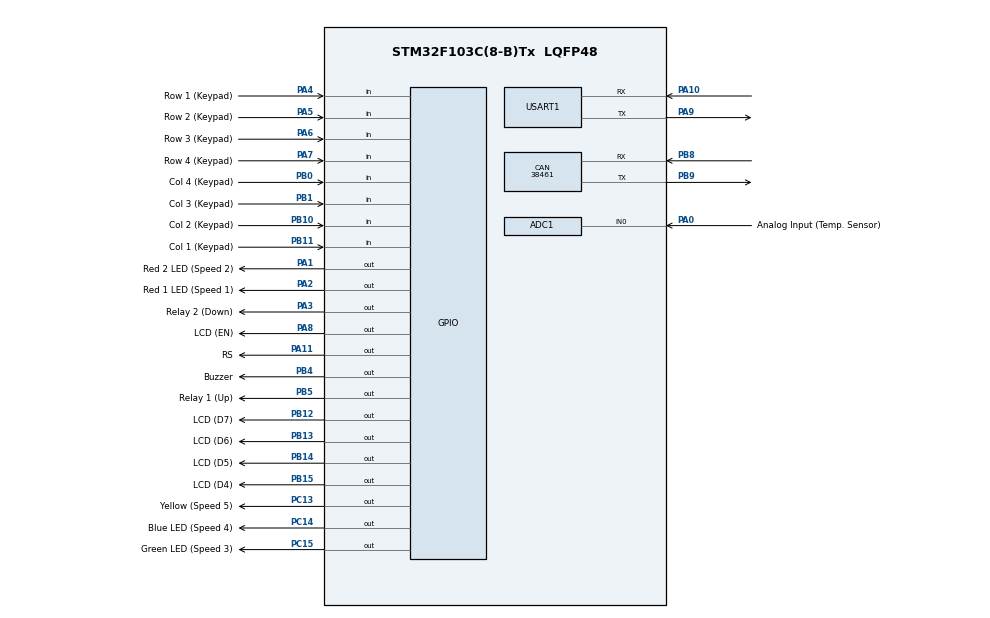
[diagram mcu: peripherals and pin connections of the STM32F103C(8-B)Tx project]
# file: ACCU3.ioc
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ADC1.Channel-0\#ChannelRegularConversion=ADC_CHANNEL_0
ADC1.NbrOfConversionFlag=1
ADC1.Rank-0\#ChannelRegularConversion=1
ADC1.SamplingTime-0\#ChannelRegularConversion=ADC_SAMPLETIME_1CYCLE_5
ADC1.master=1
CAN.BS1=CAN_BS1_8TQ
CAN.BS2=CAN_BS2_4TQ
CAN.CalculateBaudRate=38461
CAN.CalculateTimeBit=26000
CAN.CalculateTimeQuantum=2000.0
Mcu.Family=STM32F1
Mcu.Name=STM32F103C(8-B)Tx
Mcu.Package=LQFP48
NVIC.PriorityGroup=NVIC_PRIORITYGROUP_4
NVIC.TIM4_IRQn=true\:0\:0\:false\:false\:true\:true\:true\:true
PA0-WKUP.GPIO_Label=Analog Input (Temp. Sensor)
PA0-WKUP.Signal=ADCx_IN0
PA1.GPIO_Label=Red 2 LED (Speed 2)
PA1.Signal=GPIO_Output
PA10.Mode=Asynchronous
PA10.Signal=USART1_RX
PA11.GPIO_Label=RS
PA11.Signal=GPIO_Output
PA2.GPIO_Label=Red 1 LED (Speed 1)
PA2.Signal=GPIO_Output
PA3.GPIO_Label=Relay 2 (Down)
PA3.Signal=GPIO_Output
PA4.GPIO_Label=Row 1 (Keypad)
PA4.Signal=GPIO_Input
PA5.GPIO_Label=Row 2 (Keypad)
PA5.Signal=GPIO_Input
PA6.GPIO_Label=Row 3 (Keypad)
PA6.Signal=GPIO_Input
PA7.GPIO_Label=Row 4 (Keypad)
PA7.Signal=GPIO_Input
PA8.GPIO_Label=LCD (EN)
PA8.Signal=GPIO_Output
PA9.Mode=Asynchronous
PA9.Signal=USART1_TX
PB0.GPIO_Label=Col 4 (Keypad)
PB0.Signal=GPIO_Input
PB1.GPIO_Label=Col 3 (Keypad)
PB1.Signal=GPIO_Input
PB10.GPIO_Label=Col 2 (Keypad)
PB10.Signal=GPIO_Input
PB11.GPIO_Label=Col 1 (Keypad)
PB11.Signal=GPIO_Input
PB12.GPIO_Label=LCD (D7)
PB12.Signal=GPIO_Output
PB13.GPIO_Label=LCD (D6)
PB13.Signal=GPIO_Output
PB14.GPIO_Label=LCD (D5)
PB14.Signal=GPIO_Output
PB15.GPIO_Label=LCD (D4)
PB15.Signal=GPIO_Output
PB4.GPIO_Label=Buzzer
PB4.Signal=GPIO_Output
PB5.GPIO_Label=Relay 1 (Up)
PB5.Signal=GPIO_Output
PB8.Mode=CAN_Activate
PB8.Signal=CAN_RX
PB9.Mode=CAN_Activate
PB9.Signal=CAN_TX
PC13-TAMPER-RTC.GPIO_Label=Yellow (Speed 5)
PC13-TAMPER-RTC.Signal=GPIO_Output
PC14-OSC32_IN.GPIO_Label=Blue LED (Speed 4)
PC14-OSC32_IN.Signal=GPIO_Output
PC15-OSC32_OUT.GPIO_Label=Green LED (Speed 3)
PC15-OSC32_OUT.Signal=GPIO_Output
ProjectManager.HeapSize=0x200
ProjectManager.StackSize=0x400
ProjectManager.TargetToolchain=STM32CubeIDE
SH.ADCx_IN0.0=ADC1_IN0,IN0
TIM4.Channel-Output\ Compare1\ No\ Output=TIM_CHANNEL_1
TIM4.Period=1
TIM4.Prescaler=8000-1
USART1.VirtualMode=VM_ASYNC
VP_SYS_VS_ND.Mode=No_Debug
VP_TIM4_VS_ClockSourceINT.Mode=Internal
VP_TIM4_VS_no_output1.Mode=Output Compare1 No Output
board=custom

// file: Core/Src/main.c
/* USER CODE BEGIN Header */
/**
  ******************************************************************************
  * @file           : main.c
  * @brief          : Main program body
  ******************************************************************************
  * @attention
  *
  * Copyright (c) 2023 STMicroelectronics.
  * All rights reserved.
  *
  * This software is licensed under terms that can be found in the LICENSE file
  * in the root directory of this software component.
  * If no LICENSE file comes with this software, it is provided AS-IS.
  *
  ******************************************************************************
  */
/* USER CODE END Header */
#include "main.h"

ADC_HandleTypeDef hadc1;

CAN_HandleTypeDef hcan;

TIM_HandleTypeDef htim4;

UART_HandleTypeDef huart1;

void SystemClock_Config(void);
static void MX_GPIO_Init(void);
static void MX_ADC1_Init(void);
static void MX_CAN_Init(void);
static void MX_TIM4_Init(void);
static void MX_USART1_UART_Init(void);

int main(void)
{

  /* MCU Configuration--------------------------------------------------------*/

  /* Reset of all peripherals, Initializes the Flash interface and the Systick. */
  HAL_Init();

  /* Configure the system clock */
  SystemClock_Config();

  /* Initialize all configured peripherals */
  MX_GPIO_Init();
  MX_ADC1_Init();
  MX_CAN_Init();
  MX_TIM4_Init();
  MX_USART1_UART_Init();
  /* USER CODE BEGIN 2 */
  ADC_HandleTypeDef adcvar;
  /* USER CODE END 2 */

  /* Infinite loop */
  while (1)
  {

    /* USER CODE BEGIN 3 */
	  HAL_ADC_GetValue(&adcvar);
  }
  /* USER CODE END 3 */
}

void SystemClock_Config(void)
{
  RCC_OscInitTypeDef RCC_OscInitStruct = {0};
  RCC_ClkInitTypeDef RCC_ClkInitStruct = {0};
  RCC_PeriphCLKInitTypeDef PeriphClkInit = {0};

  /** Initializes the RCC Oscillators according to the specified parameters
  * in the RCC_OscInitTypeDef structure.
  */
  RCC_OscInitStruct.OscillatorType = RCC_OSCILLATORTYPE_HSI;
  RCC_OscInitStruct.HSIState = RCC_HSI_ON;
  RCC_OscInitStruct.HSICalibrationValue = RCC_HSICALIBRATION_DEFAULT;
  RCC_OscInitStruct.PLL.PLLState = RCC_PLL_NONE;
  if (HAL_RCC_OscConfig(&RCC_OscInitStruct) != HAL_OK)
  {
    Error_Handler();
  }

  /** Initializes the CPU, AHB and APB buses clocks
  */
  RCC_ClkInitStruct.ClockType = RCC_CLOCKTYPE_HCLK|RCC_CLOCKTYPE_SYSCLK
                              |RCC_CLOCKTYPE_PCLK1|RCC_CLOCKTYPE_PCLK2;
  RCC_ClkInitStruct.SYSCLKSource = RCC_SYSCLKSOURCE_HSI;
  RCC_ClkInitStruct.AHBCLKDivider = RCC_SYSCLK_DIV1;
  RCC_ClkInitStruct.APB1CLKDivider = RCC_HCLK_DIV1;
  RCC_ClkInitStruct.APB2CLKDivider = RCC_HCLK_DIV1;

  if (HAL_RCC_ClockConfig(&RCC_ClkInitStruct, FLASH_LATENCY_0) != HAL_OK)
  {
    Error_Handler();
  }
  PeriphClkInit.PeriphClockSelection = RCC_PERIPHCLK_ADC;
  PeriphClkInit.AdcClockSelection = RCC_ADCPCLK2_DIV2;
  if (HAL_RCCEx_PeriphCLKConfig(&PeriphClkInit) != HAL_OK)
  {
    Error_Handler();
  }
}

static void MX_ADC1_Init(void)
{

  ADC_ChannelConfTypeDef sConfig = {0};

  /** Common config
  */
  hadc1.Instance = ADC1;
  hadc1.Init.ScanConvMode = ADC_SCAN_DISABLE;
  hadc1.Init.ContinuousConvMode = DISABLE;
  hadc1.Init.DiscontinuousConvMode = DISABLE;
  hadc1.Init.ExternalTrigConv = ADC_SOFTWARE_START;
  hadc1.Init.DataAlign = ADC_DATAALIGN_RIGHT;
  hadc1.Init.NbrOfConversion = 1;
  if (HAL_ADC_Init(&hadc1) != HAL_OK)
  {
    Error_Handler();
  }

  /** Configure Regular Channel
  */
  sConfig.Channel = ADC_CHANNEL_0;
  sConfig.Rank = ADC_REGULAR_RANK_1;
  sConfig.SamplingTime = ADC_SAMPLETIME_1CYCLE_5;
  if (HAL_ADC_ConfigChannel(&hadc1, &sConfig) != HAL_OK)
  {
    Error_Handler();
  }

}

static void MX_CAN_Init(void)
{

  hcan.Instance = CAN1;
  hcan.Init.Prescaler = 16;
  hcan.Init.Mode = CAN_MODE_NORMAL;
  hcan.Init.SyncJumpWidth = CAN_SJW_1TQ;
  hcan.Init.TimeSeg1 = CAN_BS1_8TQ;
  hcan.Init.TimeSeg2 = CAN_BS2_4TQ;
  hcan.Init.TimeTriggeredMode = DISABLE;
  hcan.Init.AutoBusOff = DISABLE;
  hcan.Init.AutoWakeUp = DISABLE;
  hcan.Init.AutoRetransmission = DISABLE;
  hcan.Init.ReceiveFifoLocked = DISABLE;
  hcan.Init.TransmitFifoPriority = DISABLE;
  if (HAL_CAN_Init(&hcan) != HAL_OK)
  {
    Error_Handler();
  }

}

static void MX_TIM4_Init(void)
{

  TIM_ClockConfigTypeDef sClockSourceConfig = {0};
  TIM_MasterConfigTypeDef sMasterConfig = {0};
  TIM_OC_InitTypeDef sConfigOC = {0};

  htim4.Instance = TIM4;
  htim4.Init.Prescaler = 8000-1;
  htim4.Init.CounterMode = TIM_COUNTERMODE_UP;
  htim4.Init.Period = 1;
  htim4.Init.ClockDivision = TIM_CLOCKDIVISION_DIV1;
  htim4.Init.AutoReloadPreload = TIM_AUTORELOAD_PRELOAD_DISABLE;
  if (HAL_TIM_Base_Init(&htim4) != HAL_OK)
  {
    Error_Handler();
  }
  sClockSourceConfig.ClockSource = TIM_CLOCKSOURCE_INTERNAL;
  if (HAL_TIM_ConfigClockSource(&htim4, &sClockSourceConfig) != HAL_OK)
  {
    Error_Handler();
  }
  if (HAL_TIM_OC_Init(&htim4) != HAL_OK)
  {
    Error_Handler();
  }
  sMasterConfig.MasterOutputTrigger = TIM_TRGO_RESET;
  sMasterConfig.MasterSlaveMode = TIM_MASTERSLAVEMODE_DISABLE;
  if (HAL_TIMEx_MasterConfigSynchronization(&htim4, &sMasterConfig) != HAL_OK)
  {
    Error_Handler();
  }
  sConfigOC.OCMode = TIM_OCMODE_TIMING;
  sConfigOC.Pulse = 0;
  sConfigOC.OCPolarity = TIM_OCPOLARITY_HIGH;
  sConfigOC.OCFastMode = TIM_OCFAST_DISABLE;
  if (HAL_TIM_OC_ConfigChannel(&htim4, &sConfigOC, TIM_CHANNEL_1) != HAL_OK)
  {
    Error_Handler();
  }

}

static void MX_USART1_UART_Init(void)
{

  huart1.Instance = USART1;
  huart1.Init.BaudRate = 115200;
  huart1.Init.WordLength = UART_WORDLENGTH_8B;
  huart1.Init.StopBits = UART_STOPBITS_1;
  huart1.Init.Parity = UART_PARITY_NONE;
  huart1.Init.Mode = UART_MODE_TX_RX;
  huart1.Init.HwFlowCtl = UART_HWCONTROL_NONE;
  huart1.Init.OverSampling = UART_OVERSAMPLING_16;
  if (HAL_UART_Init(&huart1) != HAL_OK)
  {
    Error_Handler();
  }

}

static void MX_GPIO_Init(void)
{
  GPIO_InitTypeDef GPIO_InitStruct = {0};

  /* GPIO Ports Clock Enable */
  __HAL_RCC_GPIOC_CLK_ENABLE();
  __HAL_RCC_GPIOA_CLK_ENABLE();
  __HAL_RCC_GPIOB_CLK_ENABLE();

  /*Configure GPIO pin Output Level */
  HAL_GPIO_WritePin(GPIOC, Yellow_Pin|Blue_LED_Pin|Green_LED_Pin, GPIO_PIN_RESET);

  /*Configure GPIO pin Output Level */
  HAL_GPIO_WritePin(GPIOA, Red_2_LED_Pin|Red_1_LED_Pin|Relay_2_Pin|LCDA8_Pin
                          |RS_Pin, GPIO_PIN_RESET);

  /*Configure GPIO pin Output Level */
  HAL_GPIO_WritePin(GPIOB, LCD_Pin|LCDB13_Pin|LCDB14_Pin|LCDB15_Pin
                          |Buzzer_Pin|Relay_1_Pin, GPIO_PIN_RESET);

  /*Configure GPIO pins : Yellow_Pin Blue_LED_Pin Green_LED_Pin */
  GPIO_InitStruct.Pin = Yellow_Pin|Blue_LED_Pin|Green_LED_Pin;
  GPIO_InitStruct.Mode = GPIO_MODE_OUTPUT_PP;
  GPIO_InitStruct.Pull = GPIO_NOPULL;
  GPIO_InitStruct.Speed = GPIO_SPEED_FREQ_LOW;
  HAL_GPIO_Init(GPIOC, &GPIO_InitStruct);

  /*Configure GPIO pins : Red_2_LED_Pin Red_1_LED_Pin Relay_2_Pin LCDA8_Pin
                           RS_Pin */
  GPIO_InitStruct.Pin = Red_2_LED_Pin|Red_1_LED_Pin|Relay_2_Pin|LCDA8_Pin
                          |RS_Pin;
  GPIO_InitStruct.Mode = GPIO_MODE_OUTPUT_PP;
  GPIO_InitStruct.Pull = GPIO_NOPULL;
  GPIO_InitStruct.Speed = GPIO_SPEED_FREQ_LOW;
  HAL_GPIO_Init(GPIOA, &GPIO_InitStruct);

  /*Configure GPIO pins : Row_1_Pin Row_2_Pin Row_3_Pin Row_4_Pin */
  GPIO_InitStruct.Pin = Row_1_Pin|Row_2_Pin|Row_3_Pin|Row_4_Pin;
  GPIO_InitStruct.Mode = GPIO_MODE_INPUT;
  GPIO_InitStruct.Pull = GPIO_NOPULL;
  HAL_GPIO_Init(GPIOA, &GPIO_InitStruct);

  /*Configure GPIO pins : Col_4_Pin Col_3_Pin Col_2_Pin Col_1_Pin */
  GPIO_InitStruct.Pin = Col_4_Pin|Col_3_Pin|Col_2_Pin|Col_1_Pin;
  GPIO_InitStruct.Mode = GPIO_MODE_INPUT;
  GPIO_InitStruct.Pull = GPIO_NOPULL;
  HAL_GPIO_Init(GPIOB, &GPIO_InitStruct);

  /*Configure GPIO pins : LCD_Pin LCDB13_Pin LCDB14_Pin LCDB15_Pin
                           Buzzer_Pin Relay_1_Pin */
  GPIO_InitStruct.Pin = LCD_Pin|LCDB13_Pin|LCDB14_Pin|LCDB15_Pin
                          |Buzzer_Pin|Relay_1_Pin;
  GPIO_InitStruct.Mode = GPIO_MODE_OUTPUT_PP;
  GPIO_InitStruct.Pull = GPIO_NOPULL;
  GPIO_InitStruct.Speed = GPIO_SPEED_FREQ_LOW;
  HAL_GPIO_Init(GPIOB, &GPIO_InitStruct);

}

void Error_Handler(void)
{
  __disable_irq();
  while (1)
  {
  }
}
